# Espressif register map
File version: 1.0
CPU: Xtensa LX6 1, little endian, no MPU, FPU, 3 interrupt priority bits
Registers are 32-bit, access not given, reset 0x0 unless marked. A register's access mark holds for its fields unless they carry their own. Offsets are from the block's base; [hi:lo] are bit positions; {n}, {i} and the like mark numbered series.

## SPI
Base 0x00000000
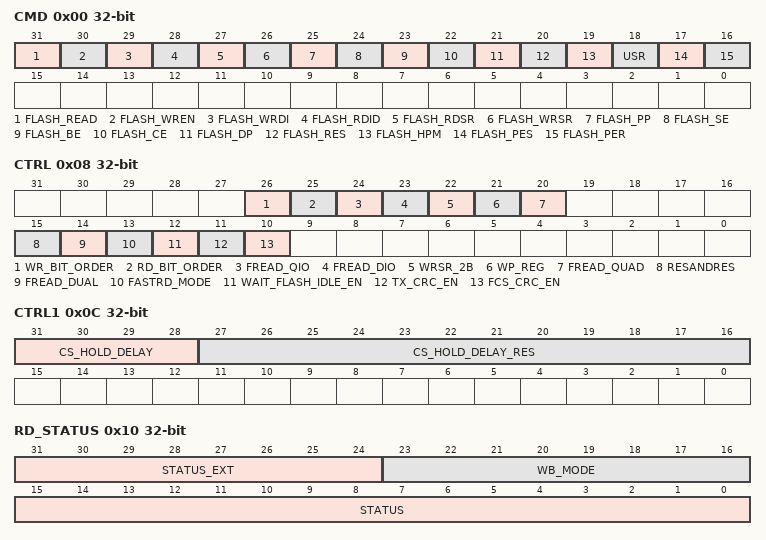
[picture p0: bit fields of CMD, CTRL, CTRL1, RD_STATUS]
0x00 CMD — SPI_CMD
  [31] FLASH_READ, [30] FLASH_WREN, [29] FLASH_WRDI, [28] FLASH_RDID, [27] FLASH_RDSR, [26] FLASH_WRSR, [25] FLASH_PP, [24] FLASH_SE, [23] FLASH_BE, [22] FLASH_CE, [21] FLASH_DP, [20] FLASH_RES, [19] FLASH_HPM, [18] USR, [17] FLASH_PES, [16] FLASH_PER
0x08 CTRL — SPI_CTRL
  [26] WR_BIT_ORDER, [25] RD_BIT_ORDER, [24] FREAD_QIO, [23] FREAD_DIO, [22] WRSR_2B, [21] WP_REG, [20] FREAD_QUAD, [15] RESANDRES, [14] FREAD_DUAL, [13] FASTRD_MODE, [12] WAIT_FLASH_IDLE_EN, [11] TX_CRC_EN, [10] FCS_CRC_EN
0x0C CTRL1 — SPI_CTRL1
  [31:28] CS_HOLD_DELAY, [27:16] CS_HOLD_DELAY_RES
0x10 RD_STATUS — SPI_RD_STATUS
  [31:24] STATUS_EXT, [23:16] WB_MODE, [15:0] STATUS
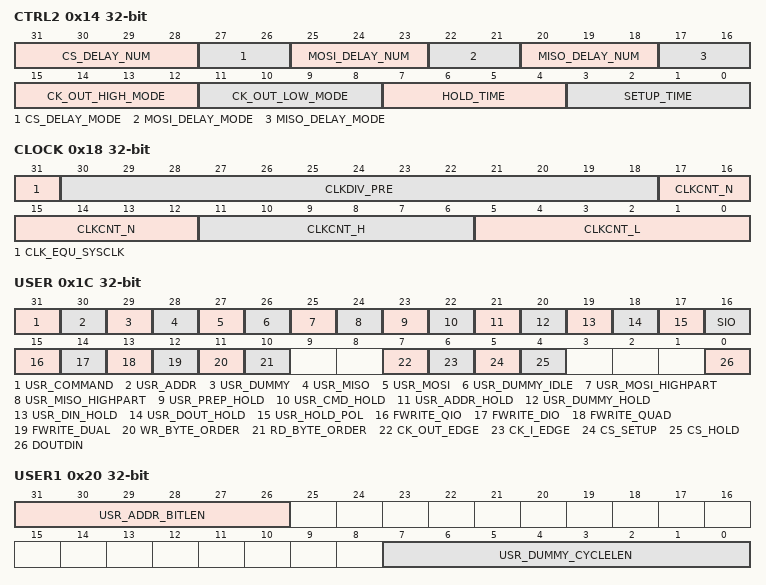
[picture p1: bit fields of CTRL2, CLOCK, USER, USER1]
0x14 CTRL2 — SPI_CTRL2
  [31:28] CS_DELAY_NUM, [27:26] CS_DELAY_MODE, [25:23] MOSI_DELAY_NUM, [22:21] MOSI_DELAY_MODE, [20:18] MISO_DELAY_NUM, [17:16] MISO_DELAY_MODE, [15:12] CK_OUT_HIGH_MODE, [11:8] CK_OUT_LOW_MODE, [7:4] HOLD_TIME, [3:0] SETUP_TIME
0x18 CLOCK — SPI_CLOCK
  [31] CLK_EQU_SYSCLK, [30:18] CLKDIV_PRE, [17:12] CLKCNT_N, [11:6] CLKCNT_H, [5:0] CLKCNT_L
0x1C USER — SPI_USER
  [31] USR_COMMAND, [30] USR_ADDR, [29] USR_DUMMY, [28] USR_MISO, [27] USR_MOSI, [26] USR_DUMMY_IDLE, [25] USR_MOSI_HIGHPART, [24] USR_MISO_HIGHPART, [23] USR_PREP_HOLD, [22] USR_CMD_HOLD, [21] USR_ADDR_HOLD, [20] USR_DUMMY_HOLD, [19] USR_DIN_HOLD, [18] USR_DOUT_HOLD, [17] USR_HOLD_POL, [16] SIO, [15] FWRITE_QIO, [14] FWRITE_DIO, [13] FWRITE_QUAD, [12] FWRITE_DUAL, [11] WR_BYTE_ORDER, [10] RD_BYTE_ORDER, [7] CK_OUT_EDGE, [6] CK_I_EDGE, [5] CS_SETUP, [4] CS_HOLD, [0] DOUTDIN
0x20 USER1 — SPI_USER1
  [31:26] USR_ADDR_BITLEN, [7:0] USR_DUMMY_CYCLELEN
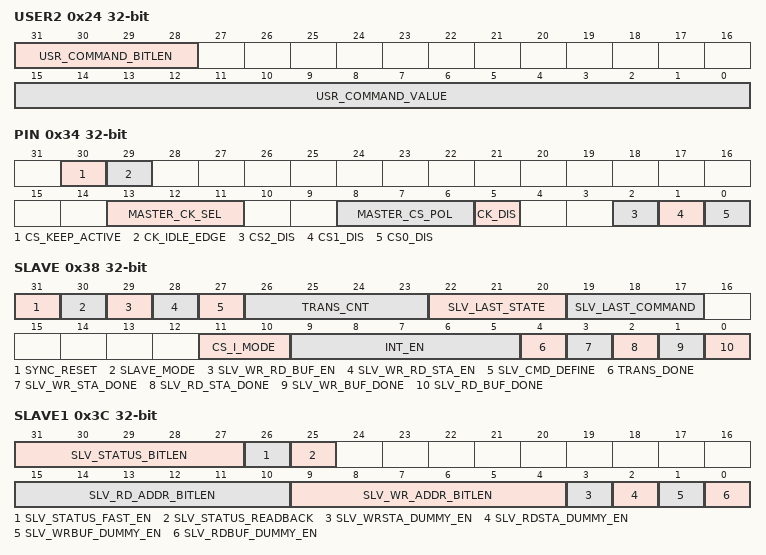
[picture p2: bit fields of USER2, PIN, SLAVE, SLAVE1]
0x24 USER2 — SPI_USER2
  [31:28] USR_COMMAND_BITLEN, [15:0] USR_COMMAND_VALUE
0x28 MOSI_DLEN — SPI_MOSI_DLEN
  [23:0] USR_MOSI_DBITLEN
0x2C MISO_DLEN — SPI_MISO_DLEN
  [23:0] USR_MISO_DBITLEN
0x30 SLV_WR_STATUS — SPI_SLV_WR_STATUS
  [31:0] SLV_WR_ST
0x34 PIN — SPI_PIN
  [30] CS_KEEP_ACTIVE, [29] CK_IDLE_EDGE, [13:11] MASTER_CK_SEL, [8:6] MASTER_CS_POL, [5] CK_DIS, [2] CS2_DIS, [1] CS1_DIS, [0] CS0_DIS
0x38 SLAVE — SPI_SLAVE
  [31] SYNC_RESET, [30] SLAVE_MODE, [29] SLV_WR_RD_BUF_EN, [28] SLV_WR_RD_STA_EN, [27] SLV_CMD_DEFINE, [26:23] TRANS_CNT, [22:20] SLV_LAST_STATE, [19:17] SLV_LAST_COMMAND, [11:10] CS_I_MODE, [9:5] INT_EN, [4] TRANS_DONE, [3] SLV_WR_STA_DONE, [2] SLV_RD_STA_DONE, [1] SLV_WR_BUF_DONE, [0] SLV_RD_BUF_DONE
0x3C SLAVE1 — SPI_SLAVE1
  [31:27] SLV_STATUS_BITLEN, [26] SLV_STATUS_FAST_EN, [25] SLV_STATUS_READBACK, [15:10] SLV_RD_ADDR_BITLEN, [9:4] SLV_WR_ADDR_BITLEN, [3] SLV_WRSTA_DUMMY_EN, [2] SLV_RDSTA_DUMMY_EN, [1] SLV_WRBUF_DUMMY_EN, [0] SLV_RDBUF_DUMMY_EN
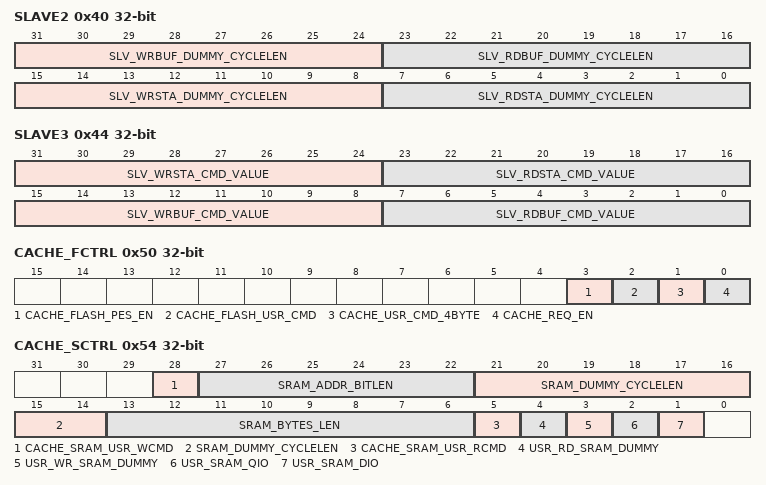
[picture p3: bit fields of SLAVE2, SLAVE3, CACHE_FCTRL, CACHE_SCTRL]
0x40 SLAVE2 — SPI_SLAVE2
  [31:24] SLV_WRBUF_DUMMY_CYCLELEN, [23:16] SLV_RDBUF_DUMMY_CYCLELEN, [15:8] SLV_WRSTA_DUMMY_CYCLELEN, [7:0] SLV_RDSTA_DUMMY_CYCLELEN
0x44 SLAVE3 — SPI_SLAVE3
  [31:24] SLV_WRSTA_CMD_VALUE, [23:16] SLV_RDSTA_CMD_VALUE, [15:8] SLV_WRBUF_CMD_VALUE, [7:0] SLV_RDBUF_CMD_VALUE
0x48 SLV_WRBUF_DLEN — SPI_SLV_WRBUF_DLEN
  [23:0] SLV_WRBUF_DBITLEN
0x4C SLV_RDBUF_DLEN — SPI_SLV_RDBUF_DLEN
  [23:0] SLV_RDBUF_DBITLEN
0x50 CACHE_FCTRL — SPI_CACHE_FCTRL
  [3] CACHE_FLASH_PES_EN, [2] CACHE_FLASH_USR_CMD, [1] CACHE_USR_CMD_4BYTE, [0] CACHE_REQ_EN
0x54 CACHE_SCTRL — SPI_CACHE_SCTRL
  [28] CACHE_SRAM_USR_WCMD, [27:22] SRAM_ADDR_BITLEN, [21:14] SRAM_DUMMY_CYCLELEN, [13:6] SRAM_BYTES_LEN, [5] CACHE_SRAM_USR_RCMD, [4] USR_RD_SRAM_DUMMY, [3] USR_WR_SRAM_DUMMY, [2] USR_SRAM_QIO, [1] USR_SRAM_DIO
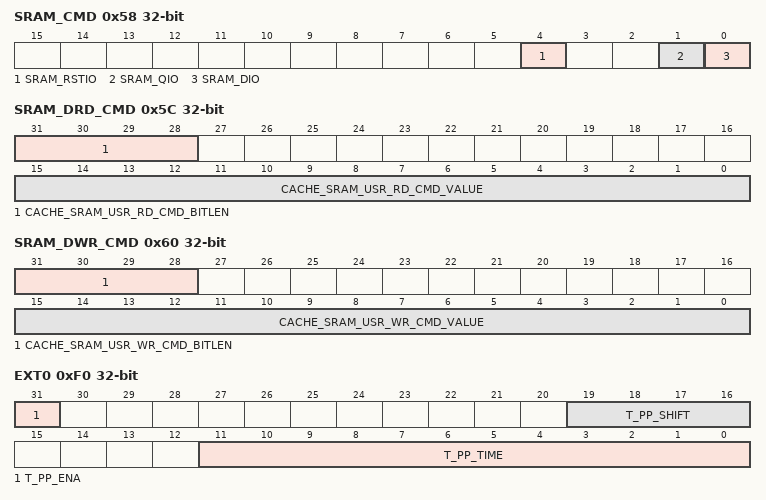
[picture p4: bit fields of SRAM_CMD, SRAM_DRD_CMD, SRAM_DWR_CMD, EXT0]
0x58 SRAM_CMD — SPI_SRAM_CMD
  [4] SRAM_RSTIO, [1] SRAM_QIO, [0] SRAM_DIO
0x5C SRAM_DRD_CMD — SPI_SRAM_DRD_CMD
  [31:28] CACHE_SRAM_USR_RD_CMD_BITLEN, [15:0] CACHE_SRAM_USR_RD_CMD_VALUE
0x60 SRAM_DWR_CMD — SPI_SRAM_DWR_CMD
  [31:28] CACHE_SRAM_USR_WR_CMD_BITLEN, [15:0] CACHE_SRAM_USR_WR_CMD_VALUE
0x64 SLV_RD_BIT — SPI_SLV_RD_BIT
  [23:0] SLV_RDATA_BIT
{0x80+4i} W{i} (i=0..15) — SPI_W{i}
  [31:0] BUF{i}
0xC0 TX_CRC — SPI_TX_CRC
  [31:0] TX_CRC_DATA
0xF0 EXT0 — SPI_EXT0
  [31] T_PP_ENA, [19:16] T_PP_SHIFT, [11:0] T_PP_TIME
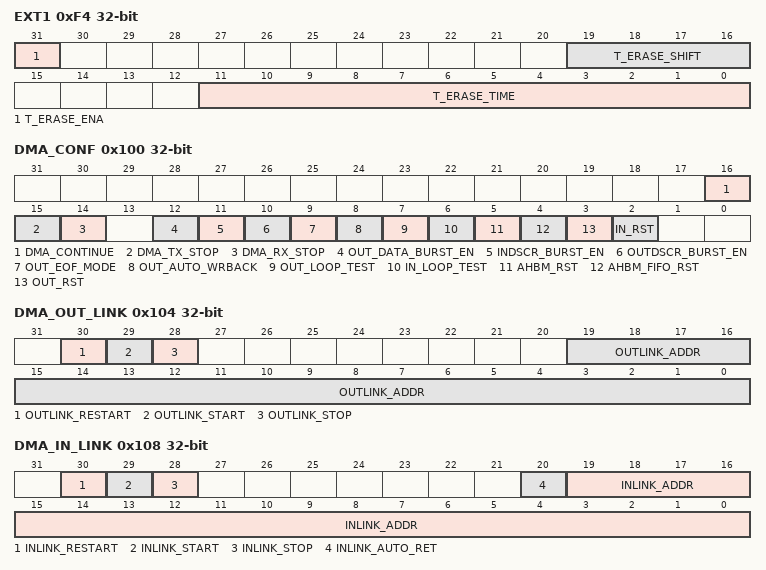
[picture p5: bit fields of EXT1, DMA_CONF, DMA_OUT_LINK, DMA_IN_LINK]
0xF4 EXT1 — SPI_EXT1
  [31] T_ERASE_ENA, [19:16] T_ERASE_SHIFT, [11:0] T_ERASE_TIME
0xF8 EXT2 — SPI_EXT2
  [2:0] ST
0xFC EXT3 — SPI_EXT3
  [1:0] INT_HOLD_ENA
0x100 DMA_CONF — SPI_DMA_CONF
  [16] DMA_CONTINUE, [15] DMA_TX_STOP, [14] DMA_RX_STOP, [12] OUT_DATA_BURST_EN, [11] INDSCR_BURST_EN, [10] OUTDSCR_BURST_EN, [9] OUT_EOF_MODE, [8] OUT_AUTO_WRBACK, [7] OUT_LOOP_TEST, [6] IN_LOOP_TEST, [5] AHBM_RST, [4] AHBM_FIFO_RST, [3] OUT_RST, [2] IN_RST
0x104 DMA_OUT_LINK — SPI_DMA_OUT_LINK
  [30] OUTLINK_RESTART, [29] OUTLINK_START, [28] OUTLINK_STOP, [19:0] OUTLINK_ADDR
0x108 DMA_IN_LINK — SPI_DMA_IN_LINK
  [30] INLINK_RESTART, [29] INLINK_START, [28] INLINK_STOP, [20] INLINK_AUTO_RET, [19:0] INLINK_ADDR
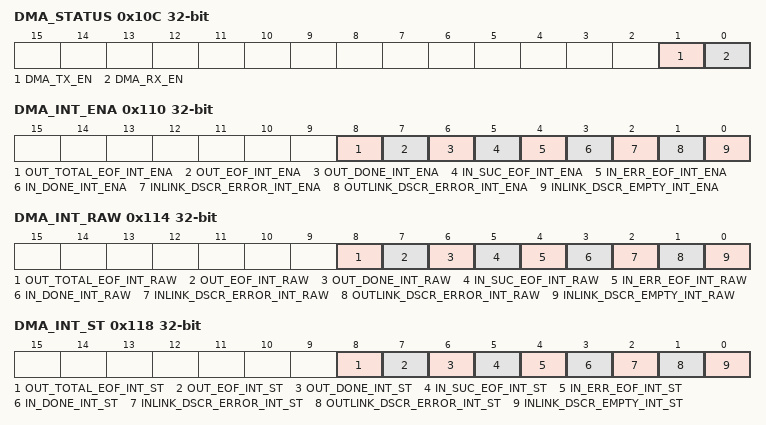
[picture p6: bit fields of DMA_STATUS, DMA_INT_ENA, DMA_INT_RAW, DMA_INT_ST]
0x10C DMA_STATUS — SPI_DMA_STATUS
  [1] DMA_TX_EN, [0] DMA_RX_EN
0x110 DMA_INT_ENA — SPI_DMA_INT_ENA
  [8] OUT_TOTAL_EOF_INT_ENA, [7] OUT_EOF_INT_ENA, [6] OUT_DONE_INT_ENA, [5] IN_SUC_EOF_INT_ENA, [4] IN_ERR_EOF_INT_ENA, [3] IN_DONE_INT_ENA, [2] INLINK_DSCR_ERROR_INT_ENA, [1] OUTLINK_DSCR_ERROR_INT_ENA, [0] INLINK_DSCR_EMPTY_INT_ENA
0x114 DMA_INT_RAW — SPI_DMA_INT_RAW
  [8] OUT_TOTAL_EOF_INT_RAW, [7] OUT_EOF_INT_RAW, [6] OUT_DONE_INT_RAW, [5] IN_SUC_EOF_INT_RAW, [4] IN_ERR_EOF_INT_RAW, [3] IN_DONE_INT_RAW, [2] INLINK_DSCR_ERROR_INT_RAW, [1] OUTLINK_DSCR_ERROR_INT_RAW, [0] INLINK_DSCR_EMPTY_INT_RAW
0x118 DMA_INT_ST — SPI_DMA_INT_ST
  [8] OUT_TOTAL_EOF_INT_ST, [7] OUT_EOF_INT_ST, [6] OUT_DONE_INT_ST, [5] IN_SUC_EOF_INT_ST, [4] IN_ERR_EOF_INT_ST, [3] IN_DONE_INT_ST, [2] INLINK_DSCR_ERROR_INT_ST, [1] OUTLINK_DSCR_ERROR_INT_ST, [0] INLINK_DSCR_EMPTY_INT_ST
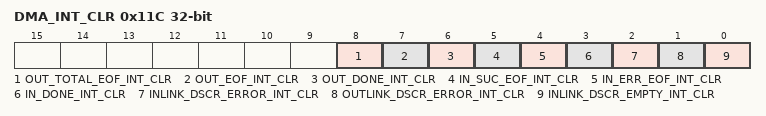
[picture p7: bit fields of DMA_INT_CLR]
0x11C DMA_INT_CLR — SPI_DMA_INT_CLR
  [8] OUT_TOTAL_EOF_INT_CLR, [7] OUT_EOF_INT_CLR, [6] OUT_DONE_INT_CLR, [5] IN_SUC_EOF_INT_CLR, [4] IN_ERR_EOF_INT_CLR, [3] IN_DONE_INT_CLR, [2] INLINK_DSCR_ERROR_INT_CLR, [1] OUTLINK_DSCR_ERROR_INT_CLR, [0] INLINK_DSCR_EMPTY_INT_CLR
0x120 IN_ERR_EOF_DES_ADDR — SPI_IN_ERR_EOF_DES_ADDR
  [31:0] DMA_IN_ERR_EOF_DES_ADDR
0x124 IN_SUC_EOF_DES_ADDR — SPI_IN_SUC_EOF_DES_ADDR
  [31:0] DMA_IN_SUC_EOF_DES_ADDR
0x128 INLINK_DSCR — SPI_INLINK_DSCR
  [31:0] DMA_INLINK_DSCR
0x12C INLINK_DSCR_BF0 — SPI_INLINK_DSCR_BF0
  [31:0] DMA_INLINK_DSCR_BF0
0x130 INLINK_DSCR_BF1 — SPI_INLINK_DSCR_BF1
  [31:0] DMA_INLINK_DSCR_BF1
0x134 OUT_EOF_BFR_DES_ADDR — SPI_OUT_EOF_BFR_DES_ADDR
  [31:0] DMA_OUT_EOF_BFR_DES_ADDR
0x138 OUT_EOF_DES_ADDR — SPI_OUT_EOF_DES_ADDR
  [31:0] DMA_OUT_EOF_DES_ADDR
0x13C OUTLINK_DSCR — SPI_OUTLINK_DSCR
  [31:0] DMA_OUTLINK_DSCR
0x140 OUTLINK_DSCR_BF0 — SPI_OUTLINK_DSCR_BF0
  [31:0] DMA_OUTLINK_DSCR_BF0
0x144 OUTLINK_DSCR_BF1 — SPI_OUTLINK_DSCR_BF1
  [31:0] DMA_OUTLINK_DSCR_BF1
0x148 DMA_RSTATUS — SPI_DMA_RSTATUS
  [31:0] DMA_OUT_STATUS
0x14C DMA_TSTATUS — SPI_DMA_TSTATUS
  [31:0] DMA_IN_STATUS
0x3FC DATE — SPI_DATE
  [27:0] DATE
